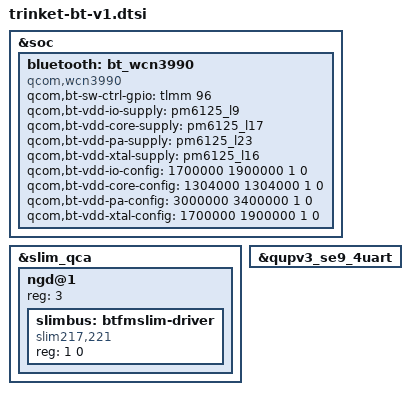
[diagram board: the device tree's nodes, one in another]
#include <dt-bindings/soc/qcom,ipcc.h>

&soc {
  bluetooth: bt_wcn3990 {
    compatible = "qcom,wcn3990";
    qcom,bt-sw-ctrl-gpio = <&tlmm 96 0>; /* SW_CTRL */
    qcom,bt-vdd-io-supply = <&pm6125_l9>;
    qcom,bt-vdd-core-supply = <&pm6125_l17>;
    qcom,bt-vdd-pa-supply = <&pm6125_l23>;
    qcom,bt-vdd-xtal-supply = <&pm6125_l16>;

    qcom,bt-vdd-io-config = <1700000 1900000 1 0>;
    qcom,bt-vdd-core-config = <1304000 1304000 1 0>;
    qcom,bt-vdd-pa-config = <3000000 3400000 1 0>;
    qcom,bt-vdd-xtal-config = <1700000 1900000 1 0>;
  };
};

&slim_qca {
  status = "ok";
  ngd@1 {
    reg = <3>;
    #address-cells = <1>;
    #size-cells = <1>;
    slimbus: btfmslim-driver {
      compatible = "slim217,221";
      reg = <1 0>;
    };
  };
};

&qupv3_se9_4uart {
  status = "ok";
};
